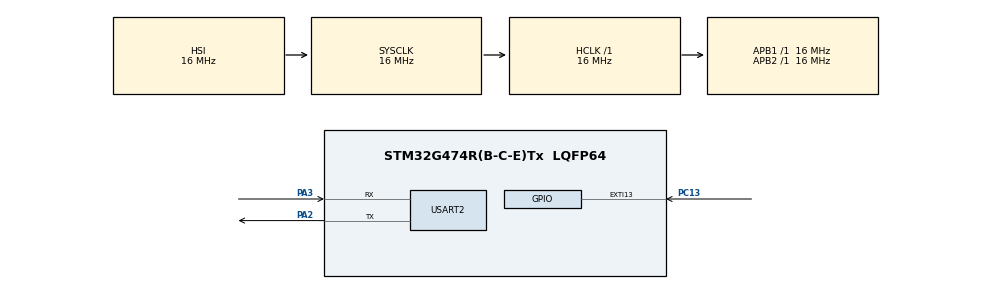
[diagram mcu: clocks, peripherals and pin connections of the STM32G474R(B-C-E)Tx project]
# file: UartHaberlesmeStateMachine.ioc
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Mcu.Family=STM32G4
Mcu.Name=STM32G474R(B-C-E)Tx
Mcu.Package=LQFP64
NVIC.EXTI15_10_IRQn=true\:0\:0\:false\:false\:true\:true\:true\:true
NVIC.PriorityGroup=NVIC_PRIORITYGROUP_4
PA2.Mode=Asynchronous
PA2.Signal=USART2_TX
PA3.Mode=Asynchronous
PA3.Signal=USART2_RX
PC13.GPIO_ModeDefaultEXTI=GPIO_MODE_IT_RISING_FALLING
PC13.Signal=GPXTI13
ProjectManager.HeapSize=0x200
ProjectManager.StackSize=0x400
ProjectManager.TargetToolchain=STM32CubeIDE
RCC.AHBFreq_Value=16000000
RCC.APB1Freq_Value=16000000
RCC.APB1TimFreq_Value=16000000
RCC.APB2Freq_Value=16000000
RCC.APB2TimFreq_Value=16000000
RCC.CortexFreq_Value=16000000
RCC.EXTERNAL_CLOCK_VALUE=12288000
RCC.HCLKFreq_Value=16000000
RCC.HSE_VALUE=8000000
RCC.HSI48_VALUE=48000000
RCC.HSI_VALUE=16000000
RCC.LSE_VALUE=32768
RCC.SYSCLKFreq_VALUE=16000000
RCC.USBFreq_Value=64000000
RCC.VCOOutputFreq_Value=128000000
USART2.VirtualMode-Asynchronous=VM_ASYNC
VP_SYS_VS_DBSignals.Mode=DisableDeadBatterySignals
board=custom

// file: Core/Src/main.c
/* USER CODE BEGIN Header */
/**
  ******************************************************************************
  * @file           : main.c
  * @brief          : Main program body
  ******************************************************************************
  * @attention
  *
  * Copyright (c) 2025 STMicroelectronics.
  * All rights reserved.
  *
  * This software is licensed under terms that can be found in the LICENSE file
  * in the root directory of this software component.
  * If no LICENSE file comes with this software, it is provided AS-IS.
  *
  ******************************************************************************
  */
/* USER CODE END Header */

#include "main.h"
#include <string.h>
#include <stdio.h>

typedef enum {
  BUTTON_IDLE,
  BUTTON_SHORT,
  BUTTON_LONG,
  BUTTON_LONGLONG
} ButtonPressType;

UART_HandleTypeDef huart2;

/* USER CODE BEGIN PV */
uint32_t button_press_time = 0;      // Butona basıldığı zamanı tutmak için
uint8_t  button_event_flag = 0;      // Buton bırakılınca setlenir
uint32_t button_elapsed_time = 0;    // Butona basılı kalınan süre (ms)
/* USER CODE END PV */

void SystemClock_Config(void);
static void MX_GPIO_Init(void);
static void MX_USART2_UART_Init(void);

/* USER CODE BEGIN PFP */
void CheckButtonPress(void);
/* USER CODE END PFP */

/* USER CODE BEGIN 0 */
#ifdef __GNUC__
  #define PUTCHAR_PROTOTYPE int __io_putchar(int ch)
#else
  #define PUTCHAR_PROTOTYPE int fputc(int ch, FILE *f)
#endif

// printf'i UART2'ye yönlendir
PUTCHAR_PROTOTYPE
{
  HAL_UART_Transmit(&huart2, (uint8_t *)&ch, 1, HAL_MAX_DELAY);
  return ch;
}
/* USER CODE END 0 */

int main(void)
{

  /* MCU Configuration--------------------------------------------------------*/
  HAL_Init();
  SystemClock_Config();
  MX_GPIO_Init();
  MX_USART2_UART_Init();

  /* Infinite loop */
  /* USER CODE BEGIN WHILE */
  while (1)
  {
    CheckButtonPress();
  }
  /* USER CODE END 3 */
}

/**
  * @brief EXTI callback (PC13)
  * @param GPIO_Pin EXTI'ye bağlı pin numarası
  * @retval None
  */
void HAL_GPIO_EXTI_Callback(uint16_t GPIO_Pin)
{
  if (GPIO_Pin == USER_BUTTON_Pin)
  {
    GPIO_PinState st = HAL_GPIO_ReadPin(USER_BUTTON_GPIO_Port, USER_BUTTON_Pin);
    if (st == GPIO_PIN_SET)
    {
      // Butona basıldı
      button_press_time = HAL_GetTick();
    }
    else
    {
      // Buton bırakıldı
      button_elapsed_time = HAL_GetTick() - button_press_time;
      button_event_flag = 1; // Ana döngüde işlem başlatılır
    }
  }
}

/*
 * Bu fonksiyon ana döngüde sürekli çağrılır.
 * Buton bırakıldığında flag setli olur, burada süreye göre karar verilir.
 */
void CheckButtonPress(void)
{
  if (button_event_flag)
  {
    ButtonPressType press_type;

    // if-else ile süreye bakarak tipi belirle
    if (button_elapsed_time < 300)
      press_type = BUTTON_SHORT;
    else if (button_elapsed_time < 1500)
      press_type = BUTTON_LONG;
    else
      press_type = BUTTON_LONGLONG;

    // switch-case ile basiş turune gore islem yap
    switch (press_type)
    {
      case BUTTON_SHORT:
        printf("Short Press! (%lu ms)\r\n", button_elapsed_time);
        break;
      case BUTTON_LONG:
        printf("Long Press! (%lu ms)\r\n", button_elapsed_time);
        break;
      case BUTTON_LONGLONG:
        printf("Long Long Press! (%lu ms)\r\n", button_elapsed_time);
        break;
      default:
        break;
    }

    // flag sıfırlanır, yeni buton işlemini bekler
    button_event_flag = 0;
  }
}

void SystemClock_Config(void)
{
  RCC_OscInitTypeDef RCC_OscInitStruct = {0};
  RCC_ClkInitTypeDef RCC_ClkInitStruct = {0};

  HAL_PWREx_ControlVoltageScaling(PWR_REGULATOR_VOLTAGE_SCALE1);

  RCC_OscInitStruct.OscillatorType = RCC_OSCILLATORTYPE_HSI;
  RCC_OscInitStruct.HSIState = RCC_HSI_ON;
  RCC_OscInitStruct.HSICalibrationValue = RCC_HSICALIBRATION_DEFAULT;
  RCC_OscInitStruct.PLL.PLLState = RCC_PLL_NONE;
  if (HAL_RCC_OscConfig(&RCC_OscInitStruct) != HAL_OK)
    Error_Handler();

  RCC_ClkInitStruct.ClockType = RCC_CLOCKTYPE_HCLK|RCC_CLOCKTYPE_SYSCLK|
                               RCC_CLOCKTYPE_PCLK1|RCC_CLOCKTYPE_PCLK2;
  RCC_ClkInitStruct.SYSCLKSource = RCC_SYSCLKSOURCE_HSI;
  RCC_ClkInitStruct.AHBCLKDivider = RCC_SYSCLK_DIV1;
  RCC_ClkInitStruct.APB1CLKDivider = RCC_HCLK_DIV1;
  RCC_ClkInitStruct.APB2CLKDivider = RCC_HCLK_DIV1;
  if (HAL_RCC_ClockConfig(&RCC_ClkInitStruct, FLASH_LATENCY_0) != HAL_OK)
    Error_Handler();
}

static void MX_USART2_UART_Init(void)
{
  huart2.Instance = USART2;
  huart2.Init.BaudRate = 115200;
  huart2.Init.WordLength = UART_WORDLENGTH_8B;
  huart2.Init.StopBits = UART_STOPBITS_1;
  huart2.Init.Parity = UART_PARITY_NONE;
  huart2.Init.Mode = UART_MODE_TX_RX;
  huart2.Init.HwFlowCtl = UART_HWCONTROL_NONE;
  huart2.Init.OverSampling = UART_OVERSAMPLING_16;
  if (HAL_UART_Init(&huart2) != HAL_OK)
    Error_Handler();
}

static void MX_GPIO_Init(void)
{
  GPIO_InitTypeDef GPIO_InitStruct = {0};

  /* GPIO Ports Clock Enable */
  __HAL_RCC_GPIOA_CLK_ENABLE();
  __HAL_RCC_GPIOC_CLK_ENABLE();

  /* PC13 (USER BUTTON): EXTI (Interrupt), No Pull, Rising+Falling Edge */
  GPIO_InitStruct.Pin = USER_BUTTON_Pin;
  GPIO_InitStruct.Mode = GPIO_MODE_IT_RISING_FALLING;
  GPIO_InitStruct.Pull = GPIO_NOPULL;
  HAL_GPIO_Init(USER_BUTTON_GPIO_Port, &GPIO_InitStruct);

  /* EXTI15_10 IRQ Enable (PC13 için) */
  HAL_NVIC_SetPriority(EXTI15_10_IRQn, 0, 0);
  HAL_NVIC_EnableIRQ(EXTI15_10_IRQn);
}

/**
  * @brief  Hata oluşursa çağrılan fonksiyon
  * @retval None
  */
void Error_Handler(void)
{
  __disable_irq();
  while (1)
  {
  }
}
